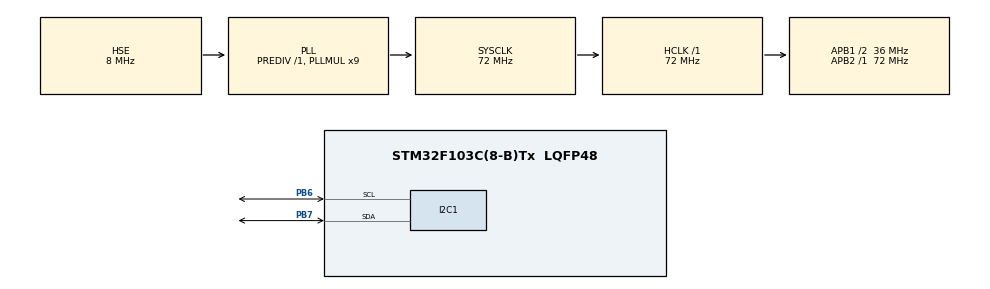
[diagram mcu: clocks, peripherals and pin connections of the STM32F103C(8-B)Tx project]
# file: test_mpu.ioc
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I2C1.I2C_Mode=I2C_Fast
Mcu.Family=STM32F1
Mcu.Name=STM32F103C(8-B)Tx
Mcu.Package=LQFP48
NVIC.PriorityGroup=NVIC_PRIORITYGROUP_4
PA13.Mode=Serial_Wire
PA13.Signal=SYS_JTMS-SWDIO
PA14.Mode=Serial_Wire
PA14.Signal=SYS_JTCK-SWCLK
PB6.Mode=I2C
PB6.Signal=I2C1_SCL
PB7.Mode=I2C
PB7.Signal=I2C1_SDA
PD0-OSC_IN.Mode=HSE-External-Oscillator
PD0-OSC_IN.Signal=RCC_OSC_IN
PD1-OSC_OUT.Mode=HSE-External-Oscillator
PD1-OSC_OUT.Signal=RCC_OSC_OUT
ProjectManager.HeapSize=0x200
ProjectManager.StackSize=0x400
ProjectManager.TargetToolchain=MDK-ARM V5.32
RCC.AHBFreq_Value=72000000
RCC.APB1CLKDivider=RCC_HCLK_DIV2
RCC.APB1Freq_Value=36000000
RCC.APB1TimFreq_Value=72000000
RCC.APB2Freq_Value=72000000
RCC.APB2TimFreq_Value=72000000
RCC.HCLKFreq_Value=72000000
RCC.PLLMUL=RCC_PLL_MUL9
RCC.PLLSourceVirtual=RCC_PLLSOURCE_HSE
RCC.SYSCLKFreq_VALUE=72000000
RCC.SYSCLKSource=RCC_SYSCLKSOURCE_PLLCLK
RCC.USBFreq_Value=72000000
VP_TIM1_VS_ClockSourceINT.Mode=Internal
board=custom

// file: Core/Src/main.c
/* USER CODE BEGIN Header */
/**
  ******************************************************************************
  * @file           : main.c
  * @brief          : Main program body
  ******************************************************************************
  * @attention
  *
  * Copyright (c) 2025 STMicroelectronics.
  * All rights reserved.
  *
  * This software is licensed under terms that can be found in the LICENSE file
  * in the root directory of this software component.
  * If no LICENSE file comes with this software, it is provided AS-IS.
  *
  ******************************************************************************
  */
/* USER CODE END Header */
#include "main.h"

/* USER CODE BEGIN Includes */
#include "math.h"
#include "MPU6050.h"
/* USER CODE END Includes */

/* USER CODE BEGIN PD */
//#define MPU6050_ADDR 0x68<<1
//#define PI           3.141592
//
//#define ax_offset -2177
//#define ay_offset  3725
//#define az_offset  2130
//#define gx_offset -80
//#define gy_offset -17
//#define gz_offset -26
/* USER CODE END PD */

I2C_HandleTypeDef hi2c1;

TIM_HandleTypeDef htim1;

void SystemClock_Config(void);
static void MX_GPIO_Init(void);
static void MX_I2C1_Init(void);
static void MX_TIM1_Init(void);
/* USER CODE BEGIN PFP */
//int16_t Accel_X_RAW = 0;
//int16_t Accel_Y_RAW = 0;
//int16_t Accel_Z_RAW = 0;
//
//int16_t Gyro_X_RAW = 0;
//int16_t Gyro_Y_RAW = 0;
//int16_t Gyro_Z_RAW = 0;

float Ax, Ay, Az, Gx, Gy, Gz;
//const float dt = 10000/1000000.0f;
//float roll  = 0.0;
/* USER CODE END PFP */

/* USER CODE BEGIN 0 */
//void MPU6050_Init(void){
//  uint8_t check, Data;
//	// check device ID WHO_AM_I
//	HAL_I2C_Mem_Read(&hi2c1, MPU6050_ADDR, 0x75, 1, &check, 1, 1000);
//	if(check == 0x68)//if the device is present
//	{
//		Data = 0;
//		HAL_I2C_Mem_Write(&hi2c1, MPU6050_ADDR, 0x6B, 1,&Data, 1, 1000);
//		// Set DATA RATE of 1KHz by writing SMPLRT_DIV register
//		Data = 0x07;
//		HAL_I2C_Mem_Write(&hi2c1, MPU6050_ADDR, 0x19, 1, &Data, 1, 1000);
//
//		Data = 0x00;
//        HAL_I2C_Mem_Write(&hi2c1, MPU6050_ADDR, 0x1A, 1, &Data, 1, 1000);
//
//		// Set Gyroscopic configuration in GYRO_CONFIG Register
//		Data = 0x00;  // XG_ST=0,YG_ST=0,ZG_ST=0, FS_SEL=0 -> ? 250 ?/s
//		HAL_I2C_Mem_Write(&hi2c1, MPU6050_ADDR, 0x1B, 1, &Data, 1, 1000);
//
//		// Set accelerometer configuration in ACCEL_CONFIG Register
//		Data = 0x00;  // XA_ST=0,YA_ST=0,ZA_ST=0, FS_SEL=0 -> ? 2g
//		HAL_I2C_Mem_Write(&hi2c1, MPU6050_ADDR, 0x1C, 1, &Data, 1, 1000);
//	}
//}
//
//void MPU6050_Read_Accel (void)
//{
//	uint8_t Rec_Data[6];
//
//	// Read 6 BYTES of data starting from ACCEL_XOUT_H (0x3B) register
//	HAL_I2C_Mem_Read (&hi2c1, 0x68<<1, 0x3B, 1, Rec_Data, 6, 100);
//
//	Accel_X_RAW = (int16_t)(Rec_Data[0] << 8 | Rec_Data [1]);
//	Accel_Y_RAW = (int16_t)(Rec_Data[2] << 8 | Rec_Data [3]);
//	Accel_Z_RAW = (int16_t)(Rec_Data[4] << 8 | Rec_Data [5]);
//
//	/*** convert the RAW values into acceleration in 'g'
//	     we have to divide according to the Full scale value set in FS_SEL
//	     I have configured FS_SEL = 0. So I am dividing by 16384.0
//	     for more details check ACCEL_CONFIG Register              ****/
//
//	Ax = (float)(Accel_X_RAW-ax_offset)/16384.0;
//	Ay = (float)(Accel_Y_RAW-ay_offset)/16384.0;
//	Az = (float)(Accel_Z_RAW-az_offset)/16384.0;
//}
//
//
//void MPU6050_Read_Gyro (void)
//{
//	uint8_t Rec_Data[6];
//
//	// Read 6 BYTES of data starting from GYRO_XOUT_H register
//	HAL_I2C_Mem_Read (&hi2c1, MPU6050_ADDR, 0x43, 1, Rec_Data, 6, 100);
//
//	Gyro_X_RAW = (int16_t)(Rec_Data[0] << 8 | Rec_Data [1]);
//	Gyro_Y_RAW = (int16_t)(Rec_Data[2] << 8 | Rec_Data [3]);
//	Gyro_Z_RAW = (int16_t)(Rec_Data[4] << 8 | Rec_Data [5]);
//
//	/*** convert the RAW values into dps (?/s)
//	     we have to divide according to the Full scale value set in FS_SEL
//	     I have configured FS_SEL = 0. So I am dividing by 131.0
//	     for more details check GYRO_CONFIG Register              ****/
//
//	Gx = (float)(Gyro_X_RAW-gx_offset)/131.0;
//	Gy = (float)(Gyro_Y_RAW-gy_offset)/131.0;
//	Gz = (float)(Gyro_Z_RAW-gz_offset)/131.0;
//}
//
//void filter( float Ax, float Ay, float Az, float Gx, float Gy, float Gz){
//  float pitchG = pitch + Gx*dt;
//	float	rollG  = roll  + Gy*dt;
//
//	float pitchA = atan2(Ay, sqrt(Ax*Ax + Az*Az))*(180/PI);
//	float rollA  = atan2(Ax, sqrt(Ay*Ay + Az*Az))*(180/PI);
//
//	pitch = 0.98*pitchG + 0.02*pitchA;
//	roll  = 0.98*rollG  + 0.02*rollA;
//}
MPU6050_Raw Raw;
MPU6050_Data Angle;
/* USER CODE END 0 */

int main(void)
{

  /* MCU Configuration--------------------------------------------------------*/

  /* Reset of all peripherals, Initializes the Flash interface and the Systick. */
  HAL_Init();

  /* Configure the system clock */
  SystemClock_Config();

  /* Initialize all configured peripherals */
  MX_GPIO_Init();
  MX_I2C1_Init();
  MX_TIM1_Init();
  /* USER CODE BEGIN 2 */
  MPU6050_Init();
	HAL_Delay(1000);
  /* USER CODE END 2 */

  /* Infinite loop */
  while (1)
  {

    /* USER CODE BEGIN 3 */
//		MPU6050_Read_Gyro();
//		MPU6050_Read_Accel();
//		filter(Ax, Ay, Az, Gx, Gy, Gz);
//		HAL_Delay(100);
		MPU6050_Read_Data(&Raw);
		MPU6050_Read_Angle(&Angle);
	  HAL_Delay(100);
}
  /* USER CODE END 3 */
}

void SystemClock_Config(void)
{
  RCC_OscInitTypeDef RCC_OscInitStruct = {0};
  RCC_ClkInitTypeDef RCC_ClkInitStruct = {0};

  /** Initializes the RCC Oscillators according to the specified parameters
  * in the RCC_OscInitTypeDef structure.
  */
  RCC_OscInitStruct.OscillatorType = RCC_OSCILLATORTYPE_HSE;
  RCC_OscInitStruct.HSEState = RCC_HSE_ON;
  RCC_OscInitStruct.HSEPredivValue = RCC_HSE_PREDIV_DIV1;
  RCC_OscInitStruct.HSIState = RCC_HSI_ON;
  RCC_OscInitStruct.PLL.PLLState = RCC_PLL_ON;
  RCC_OscInitStruct.PLL.PLLSource = RCC_PLLSOURCE_HSE;
  RCC_OscInitStruct.PLL.PLLMUL = RCC_PLL_MUL9;
  if (HAL_RCC_OscConfig(&RCC_OscInitStruct) != HAL_OK)
  {
    Error_Handler();
  }

  /** Initializes the CPU, AHB and APB buses clocks
  */
  RCC_ClkInitStruct.ClockType = RCC_CLOCKTYPE_HCLK|RCC_CLOCKTYPE_SYSCLK
                              |RCC_CLOCKTYPE_PCLK1|RCC_CLOCKTYPE_PCLK2;
  RCC_ClkInitStruct.SYSCLKSource = RCC_SYSCLKSOURCE_PLLCLK;
  RCC_ClkInitStruct.AHBCLKDivider = RCC_SYSCLK_DIV1;
  RCC_ClkInitStruct.APB1CLKDivider = RCC_HCLK_DIV2;
  RCC_ClkInitStruct.APB2CLKDivider = RCC_HCLK_DIV1;

  if (HAL_RCC_ClockConfig(&RCC_ClkInitStruct, FLASH_LATENCY_2) != HAL_OK)
  {
    Error_Handler();
  }
}

static void MX_I2C1_Init(void)
{

  hi2c1.Instance = I2C1;
  hi2c1.Init.ClockSpeed = 400000;
  hi2c1.Init.DutyCycle = I2C_DUTYCYCLE_2;
  hi2c1.Init.OwnAddress1 = 0;
  hi2c1.Init.AddressingMode = I2C_ADDRESSINGMODE_7BIT;
  hi2c1.Init.DualAddressMode = I2C_DUALADDRESS_DISABLE;
  hi2c1.Init.OwnAddress2 = 0;
  hi2c1.Init.GeneralCallMode = I2C_GENERALCALL_DISABLE;
  hi2c1.Init.NoStretchMode = I2C_NOSTRETCH_DISABLE;
  if (HAL_I2C_Init(&hi2c1) != HAL_OK)
  {
    Error_Handler();
  }

}

static void MX_TIM1_Init(void)
{

  TIM_ClockConfigTypeDef sClockSourceConfig = {0};
  TIM_MasterConfigTypeDef sMasterConfig = {0};

  htim1.Instance = TIM1;
  htim1.Init.Prescaler = 0;
  htim1.Init.CounterMode = TIM_COUNTERMODE_UP;
  htim1.Init.Period = 65535;
  htim1.Init.ClockDivision = TIM_CLOCKDIVISION_DIV1;
  htim1.Init.RepetitionCounter = 0;
  htim1.Init.AutoReloadPreload = TIM_AUTORELOAD_PRELOAD_DISABLE;
  if (HAL_TIM_Base_Init(&htim1) != HAL_OK)
  {
    Error_Handler();
  }
  sClockSourceConfig.ClockSource = TIM_CLOCKSOURCE_INTERNAL;
  if (HAL_TIM_ConfigClockSource(&htim1, &sClockSourceConfig) != HAL_OK)
  {
    Error_Handler();
  }
  sMasterConfig.MasterOutputTrigger = TIM_TRGO_RESET;
  sMasterConfig.MasterSlaveMode = TIM_MASTERSLAVEMODE_DISABLE;
  if (HAL_TIMEx_MasterConfigSynchronization(&htim1, &sMasterConfig) != HAL_OK)
  {
    Error_Handler();
  }

}

static void MX_GPIO_Init(void)
{

  /* GPIO Ports Clock Enable */
  __HAL_RCC_GPIOD_CLK_ENABLE();
  __HAL_RCC_GPIOA_CLK_ENABLE();
  __HAL_RCC_GPIOB_CLK_ENABLE();

}

void Error_Handler(void)
{
  __disable_irq();
  while (1)
  {
  }
}
